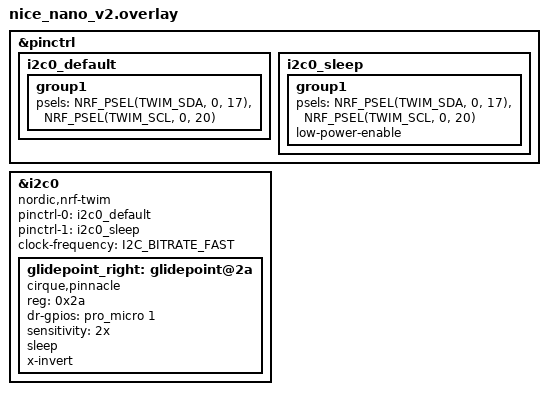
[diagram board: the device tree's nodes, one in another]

/**
 * Generated by Shield Wizard for ZMK
 * Applies to shield "miiunic_right" with board "nice_nano_v2" only
 */

//
// ======== i2c0 ========
//

// pin control for i2c0
// - SDA on D2
// - SCL on D3
&pinctrl {
    /* configuration for i2c0 device, default state */
    i2c0_default: i2c0_default {
        group1 {
            psels = <NRF_PSEL(TWIM_SDA, 0, 17)>,
                    <NRF_PSEL(TWIM_SCL, 0, 20)>;
        };
    };
    /* configuration for i2c0 device, sleep state */
    i2c0_sleep: i2c0_sleep {
        group1 {
            psels = <NRF_PSEL(TWIM_SDA, 0, 17)>,
                    <NRF_PSEL(TWIM_SCL, 0, 20)>;
            low-power-enable;
        };
    };
};
&i2c0 {
  compatible = "nordic,nrf-twim";
  status = "okay";
  pinctrl-0 = <&i2c0_default>;
  pinctrl-1 = <&i2c0_sleep>;
  pinctrl-names = "default", "sleep";
  clock-frequency = <I2C_BITRATE_FAST>;
};

// devices on i2c0

&i2c0 {
    status = "okay";

    glidepoint_right: glidepoint@2a {
        compatible = "cirque,pinnacle";
        reg = <0x2a>;
        status = "okay";
        dr-gpios = <&pro_micro 1 (GPIO_ACTIVE_HIGH)>;
        sensitivity = "2x";
        sleep;
        //no-taps;
        //y-invert;
        x-invert;
    };
};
